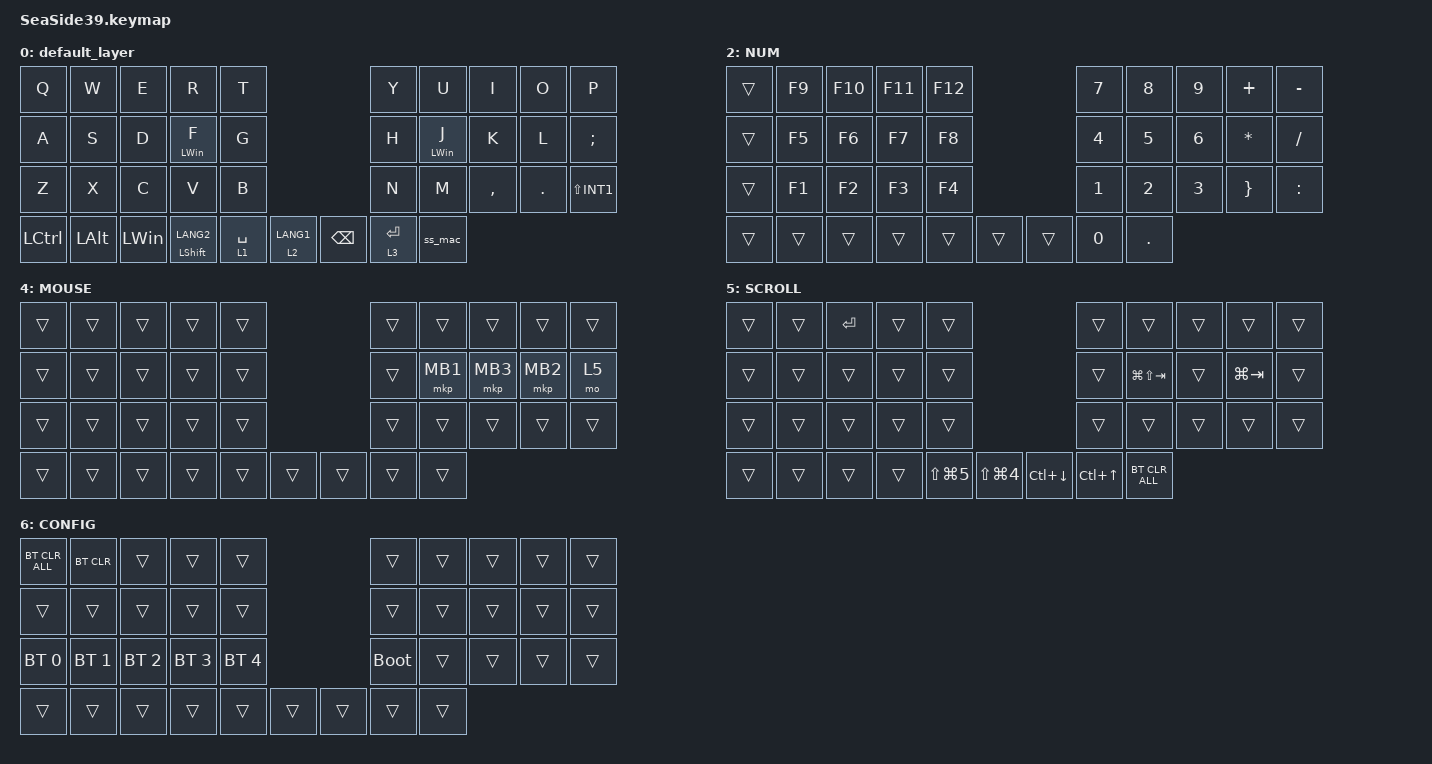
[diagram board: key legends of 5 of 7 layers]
#include <behaviors.dtsi>
#include <dt-bindings/zmk/bt.h>
#include <dt-bindings/zmk/keys.h>
#include <dt-bindings/zmk/pointing.h>
#include <input/processors.dtsi>

#define MOUSE 4
#define SCROLL 5
#define NUM 6

&mt {
    flavor = "balanced";
    quick-tap-ms = <300>;
};

&lt {
    flavor = "balanced";
    quick-tap-ms = <200>;
    tapping-term-ms = <150>;  // デフォルト200 → 150
};

/* クリック後250msでAML解除（マウスキーを押すまでレイヤーに留まる挙動） */
&mkp_input_listener {
    input-processors = <&zip_temp_layer 4 250>;
};

/ {
    combos {
        compatible = "zmk,combos";
    };

    macros {
        to_layer_0: to_layer_0 {
            compatible = "zmk,behavior-macro-one-param";
            #binding-cells = <1>;
            bindings = <&to 0 &macro_param_1to1 &kp MACRO_PLACEHOLDER>;
            label = "TO_LAYER_0";
        };

     ss_mac: ss_mac {
        compatible = "zmk,behavior-macro";
        #binding-cells = <0>;
        bindings
            = <&macro_press &kp LGUI &kp LSHFT>
            , <&macro_tap &kp N5>
            , <&macro_release &kp LGUI &kp LSHFT>;
        label = "SS_MAC";
    };
};

    behaviors {
        lt_to_layer_0: lt_to_layer_0 {
            compatible = "zmk,behavior-hold-tap";
            label = "LAYER_TAP_TO_0";
            bindings = <&mo>, <&to_layer_0>;
            #binding-cells = <2>;
            tapping-term-ms = <200>;
        };
    };

    keymap {
        compatible = "zmk,keymap";

        default_layer {
            bindings = <
&kp Q             &kp W         &kp E         &kp R             &kp T                                                &kp Y            &kp U  &kp I      &kp O     &kp P
&kp A             &kp S         &kp D         &mt LEFT_WIN F             &kp G                                                &kp H            &mt LEFT_WIN J  &kp K      &kp L     &kp SEMI
&kp Z             &kp X         &kp C         &kp V             &kp B                                                &kp N            &kp M  &kp COMMA  &kp DOT   &kp LS(INT1)
&kp LCTRL         &kp LEFT_ALT  &kp LEFT_WIN  &mt LEFT_SHIFT LANG2  &lt 1 SPACE  &lt 2 LANG1      &kp BACKSPACE  &lt 3 ENTER  &ss_mac
            >;

            sensor-bindings = <&inc_dec_kp PG_UP PAGE_DOWN>;
        };

        SYMBOL {
            bindings = <
&kp PRCNT  &kp DLLR   &kp UP     &kp CARET  &kp FSLH                             &kp BSLH  &kp LBRC  &kp RBRC  &kp LT    &kp GT
&kp AT     &kp LEFT   &kp DOWN   &kp RIGHT  &kp EQUAL                            &kp UNDER &kp LPAR  &kp RPAR  &kp SEMI  &kp COLON
&kp GRAVE  &kp TILDE  &kp MINUS  &kp EXCL   &kp QMARK                            &kp PIPE  &kp LBKT  &kp RBKT  &kp SQT   &kp DQT
&trans     &trans     &trans     &trans     &trans                               &trans    &kp COMMA &kp DOT   &trans    &kp ESC
            >;
        };

        NUM {
            bindings = <
&trans  &kp F9  &kp F10  &kp F11  &kp F12                      &kp N7  &kp N8  &kp N9  &kp PLUS  &kp MINUS
&trans  &kp F5  &kp F6   &kp F7   &kp F8                       &kp N4  &kp N5  &kp N6  &kp STAR  &kp SLASH
&trans  &kp F1  &kp F2   &kp F3   &kp F4                       &kp N1  &kp N2  &kp N3  &kp RBRC  &kp COLON
&trans  &trans  &trans   &trans   &trans   &trans      &trans  &kp N0                              &kp DOT
            >;
        };

        ARROW {
            bindings = <
&kp ESC        &kp N7  &kp N8   &kp N9   &kp STAR                     &kp LPAR                    &kp LA(LEFT)  &kp UP    &kp RA(RIGHT)              &kp LBKT
&kp TAB        &kp N4  &kp N5   &kp N6   &kp RBKT                     &kp BSLH                    &kp EXCL      &kp MINUS &kp QMARK                  &kp RC(TAB)
&kp LEFT_SHIFT &kp N1  &kp N2   &kp N3   &trans                       &kp LA(LG(LC(LEFT)))       &kp LEFT      &kp UP    &kp RIGHT                  &kp RA(RC(RG(RIGHT)))
&trans         &trans  &kp N0   &trans   &trans   &trans      &trans  &kp BACKSPACE                         &trans
            >;

            sensor-bindings = <&inc_dec_kp LC(PAGE_UP) LC(PAGE_DOWN)>;
        };

        MOUSE {
            bindings = <
&trans  &trans  &trans  &trans  &trans                      &trans  &trans    &trans    &trans    &trans
&trans  &trans  &trans  &trans  &trans                      &trans  &mkp MB1  &mkp MB3  &mkp MB2  &mo 5
&trans  &trans  &trans  &trans  &trans                      &trans  &trans    &trans    &trans    &trans
&trans  &trans  &trans  &trans  &trans  &trans      &trans  &trans                                &trans
            >;
        };

        SCROLL {
            bindings = <
&trans  &trans  &kp ENTER  &trans  &trans                                     &trans            &trans        &trans           &trans  &trans
&trans  &trans  &trans     &trans  &trans                                     &trans            &kp LG(LS(TAB))        &trans           &kp LG(TAB)  &trans
&trans  &trans  &trans     &trans  &trans                                     &trans            &trans        &trans           &trans  &trans
&trans  &trans  &trans     &trans  &kp LS(LG(N5))  &kp LS(LG(N4))      &kp LC(DOWN)  &kp LC(UP_ARROW)          &bt BT_CLR_ALL 
            >;
        };

        CONFIG {
            bindings = <
&bt BT_CLR_ALL  &bt BT_CLR    &trans        &trans        &trans                            &trans       &trans  &trans  &trans  &trans
&trans          &trans        &trans        &trans        &trans                            &trans       &trans  &trans  &trans  &trans
&bt BT_SEL 0    &bt BT_SEL 1  &bt BT_SEL 2  &bt BT_SEL 3  &bt BT_SEL 4                      &bootloader  &trans  &trans  &trans  &trans
&trans          &trans        &trans        &trans        &trans        &trans      &trans  &trans                               &trans
            >;
        };
    };
};
